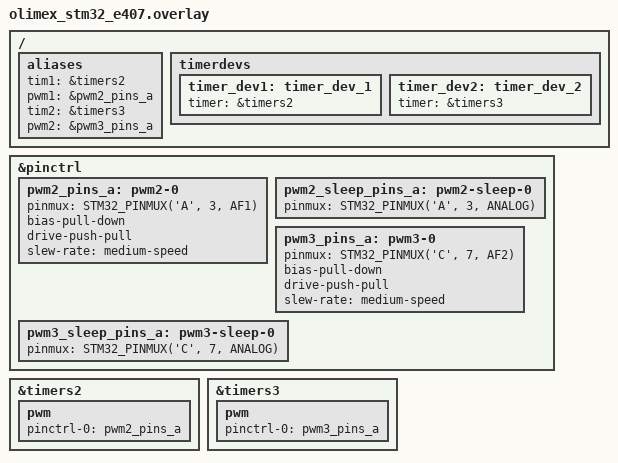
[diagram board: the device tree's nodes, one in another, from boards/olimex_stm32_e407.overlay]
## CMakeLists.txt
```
# SPDX-License-Identifier: Apache-2.0

cmake_minimum_required(VERSION 3.13.1)

set(COMPATIBLE_BOARDS olimex_stm32_e407)
if(NOT ${BOARD} IN_LIST COMPATIBLE_BOARDS)
    message(FATAL_ERROR "App $ENV{UROS_APP} not compatible with board ${BOARD}")
endif()

set(BOARD_ROOT ${CMAKE_CURRENT_LIST_DIR})

include($ENV{ZEPHYR_BASE}/cmake/app/boilerplate.cmake NO_POLICY_SCOPE)
project(microrosapp C CXX)

FILE(GLOB app_sources src/*.c)

target_sources(app PRIVATE ${app_sources})

zephyr_get_include_directories_for_lang_as_string(       C includes)
zephyr_get_system_include_directories_for_lang_as_string(C system_includes)
zephyr_get_compile_definitions_for_lang_as_string(       C definitions)
zephyr_get_compile_options_for_lang_as_string(           C options)

zephyr_get_include_directories_for_lang_as_string(       CXX includes_cxx)
zephyr_get_system_include_directories_for_lang_as_string(CXX system_includes_cxx)
zephyr_get_compile_definitions_for_lang_as_string(       CXX definitions_cxx)
zephyr_get_compile_options_for_lang_as_string(           CXX options_cxx)

set(external_project_cflags
    "${includes} ${definitions} ${options} ${system_includes}"
    )

set(external_project_cxxflags
    "${includes_cxx} ${definitions_cxx} ${options_cxx} ${system_includes_cxx}" 
    )

include(ExternalProject)

set(microros_src_dir   ${MICRO_ROS_FIRMWARE_DIR}/zephyr_apps/microros_extensions)
set(microros_build_dir ${MICRO_ROS_FIRMWARE_DIR}/build/microros_extensions)

if(CMAKE_GENERATOR STREQUAL "Unix Makefiles")
set(submake "$(MAKE)")
else()
set(submake "make")
endif()

ExternalProject_Add(
    microroslib_project                 # Name for custom target
    PREFIX     ${microros_build_dir}    # Root dir for entire project
    SOURCE_DIR ${microros_src_dir}
    BINARY_DIR ${microros_src_dir}      # This particular build system is invoked from the root
    CONFIGURE_COMMAND ""                # Skip configuring the project, e.g. with autoconf
    BUILD_COMMAND
        ${submake}
            PREFIX=${microros_src_dir}
            CC=${CMAKE_C_COMPILER}
            AR=${CMAKE_AR}
            CFLAGS=${external_project_cflags}
            CXX=${CMAKE_CXX_COMPILER}
            CXXFLAGS=${external_project_cxxflags}
            APP_META=$ENV{UROS_APP_FOLDER}/app-colcon.meta

    INSTALL_COMMAND ""      # This particular build system has no install command
    BUILD_BYPRODUCTS ${MICROROS_LIB_DIR}/libmicroros.a
    )

file(MAKE_DIRECTORY ${MICRO_ROS_FIRMWARE_DIR}/mcu_ws/install)
file(MAKE_DIRECTORY ${MICRO_ROS_FIRMWARE_DIR}/mcu_ws/install/include)

set(MICROROS_LIB_DIR     ${MICRO_ROS_FIRMWARE_DIR}/mcu_ws/install)
set(MICROROS_INCLUDE_DIR ${MICRO_ROS_FIRMWARE_DIR}/mcu_ws/install/include)

add_library(microroslib STATIC IMPORTED GLOBAL)
add_dependencies(
    microroslib
    microroslib_project
    )

add_dependencies(microroslib_project offsets_h)

set_target_properties(microroslib PROPERTIES IMPORTED_LOCATION             ${MICROROS_LIB_DIR}/libmicroros.a)
set_target_properties(microroslib PROPERTIES INTERFACE_INCLUDE_DIRECTORIES ${MICROROS_INCLUDE_DIR})

target_link_libraries(app PUBLIC microroslib)
```

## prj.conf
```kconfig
CONFIG_MAIN_STACK_SIZE=25000
CONFIG_MAIN_THREAD_PRIORITY=3

CONFIG_NEWLIB_LIBC=y
CONFIG_NEWLIB_LIBC_NANO=n
CONFIG_CPLUSPLUS=y
CONFIG_LIB_CPLUSPLUS=y
CONFIG_PTHREAD_IPC=n

CONFIG_POSIX_API=y
CONFIG_NATIVE_POSIX_TIMER=y
CONFIG_APP_LINK_WITH_POSIX_SUBSYS=y
CONFIG_POSIX_CLOCK=y

CONFIG_I2C=y
CONFIG_GPIO=y
CONFIG_PWM=y
CONFIG_SENSOR=y

CONFIG_LED_STRIP=y
CONFIG_LED_STRIP_LOG_LEVEL_DBG=y
CONFIG_WS2812_STRIP=y
CONFIG_SPI=y
CONFIG_WS2812_STRIP_GPIO=n

CONFIG_STDOUT_CONSOLE=y
CONFIG_PRINTK=y
CONFIG_USB=y
CONFIG_USB_DEVICE_STACK=y
CONFIG_USB_DEVICE_PRODUCT="Zephyr micro-ROS"
CONFIG_LOG=y
CONFIG_USB_CDC_ACM=y
CONFIG_SERIAL=y
CONFIG_UART_INTERRUPT_DRIVEN=y
CONFIG_UART_LINE_CTRL=y
CONFIG_USB_DRIVER_LOG_LEVEL_ERR=y
CONFIG_USB_DEVICE_LOG_LEVEL_ERR=y
CONFIG_USB_CDC_ACM_RINGBUF_SIZE=2048
```

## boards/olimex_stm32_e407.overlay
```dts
/{
	aliases {
		tim1 = &timers2;
		pwm1 = &pwm2_pins_a;
		tim2 = &timers3;
		pwm2 = &pwm3_pins_a;
	};

	timerdevs {
		timer_dev1: timer_dev_1 {
			timer = &timers2;
		};

		timer_dev2: timer_dev_2 {
			timer = &timers3;
		};
	};
};

&pinctrl {
	pwm2_pins_a: pwm2-0 {
		pinmux = <STM32_PINMUX('A', 3, AF1)>; /* TIM2_CH4 */
		bias-pull-down;
		drive-push-pull;
		slew-rate = "medium-speed";
	};

	pwm2_sleep_pins_a: pwm2-sleep-0 {
		pinmux = <STM32_PINMUX('A', 3, ANALOG)>; /* TIM2_CH4 */
	};

	pwm3_pins_a: pwm3-0 {
		pinmux = <STM32_PINMUX('C', 7, AF2)>; /* TIM3_CH2 */
		bias-pull-down;
		drive-push-pull;
		slew-rate = "medium-speed";
	};

	pwm3_sleep_pins_a: pwm3-sleep-0 {
		pinmux = <STM32_PINMUX('C', 7, ANALOG)>; /* TIM3_CH2 */
	};
};

&timers2 {
	status = "okay";

	pwm {
		status = "okay";
		pinctrl-0 = <&pwm2_pins_a>;
	};
};

&timers3 {
	status = "okay";

	pwm {
		status = "okay";
		pinctrl-0 = <&pwm3_pins_a>;
	};
};
```

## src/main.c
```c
#include <zephyr.h>
#include <device.h>
#include <devicetree.h>
#include <drivers/sensor.h>
#include <drivers/gpio.h>
#include <drivers/led_strip.h>
#include <drivers/pwm.h>
#include <stdio.h>
#include <sys/util.h>
#include <string.h>
#include <sys/printk.h>

#include <rcl/rcl.h>
#include <rcl/error_handling.h>
#include <rclc/rclc.h>
#include <rclc/executor.h>

#include <std_msgs/msg/bool.h>
#include <std_msgs/msg/int32.h>

#define RCCHECK(fn) { rcl_ret_t temp_rc = fn; if((temp_rc != RCL_RET_OK)){printk("Failed status on line %d: %d. Aborting.\n",__LINE__,(int)temp_rc);}}
#define RCSOFTCHECK(fn) { rcl_ret_t temp_rc = fn; if((temp_rc != RCL_RET_OK)){printk("Failed status on line %d: %d. Continuing.\n",__LINE__,(int)temp_rc);}}

//#define PWM_DRIVER	DT_ALIAS_PWM_LED0_PWMS_CONTROLLER
#define PIN	DT_GPIO_PIN(DT_ALIAS(led0), gpios)
static struct device *led;

static const struct device *pwm1;
static const struct device *pwm2;

rcl_subscription_t pwm1_subscription;
rcl_subscription_t pwm2_subscription;

std_msgs__msg__Int32 pwm1_msg;
std_msgs__msg__Int32 pwm2_msg;

void pwm1_subscription_callback(const void * msg)
{
}

void pwm2_subscription_callback(const void * msg)
{
}

void main(void)
{
	led = device_get_binding(DT_GPIO_LABEL(DT_ALIAS(led0), gpios));
	gpio_pin_configure(led, PIN, GPIO_OUTPUT_ACTIVE);

	rcl_allocator_t allocator = rcl_get_default_allocator();
	rclc_support_t support;

	// create init_options
	RCCHECK(rclc_support_init(&support, 0, NULL, &allocator));

	// create node
	rcl_node_t node;
	RCCHECK(rclc_node_init_default(&node, "bfr_hardware_node", "", &support));

	uint32_t pwm1_pinmux = DT_PROP(DT_ALIAS(pwm1), pinmux);
	uint32_t pwm2_pinmux = DT_PROP(DT_ALIAS(pwm2), pinmux);

	// ---- Devices configuration ----
	pwm1 = device_get_binding(DT_LABEL(DT_CHILD(DT_ALIAS(tim1), pwm)));
	pwm2 = device_get_binding(DT_LABEL(DT_CHILD(DT_ALIAS(tim2), pwm)));

	uint64_t cycles = 0;

	RCCHECK(rclc_subscription_init_default(&pwm1_subscription, &node, ROSIDL_GET_MSG_TYPE_SUPPORT(std_msgs, msg, Int32), "/hal/hardware/pwm1"));
	RCCHECK(rclc_subscription_init_default(&pwm2_subscription, &node, ROSIDL_GET_MSG_TYPE_SUPPORT(std_msgs, msg, Int32), "/hal/hardware/pwm2"));

	// Creating a executor
	rclc_executor_t executor;
	RCCHECK(rclc_executor_init(&executor, &support.context, 2, &allocator));
	RCCHECK(rclc_executor_add_subscription(&executor, &pwm1_subscription, &pwm1_msg, &pwm1_subscription_callback, ON_NEW_DATA));
	RCCHECK(rclc_executor_add_subscription(&executor, &pwm2_subscription, &pwm2_msg, &pwm2_subscription_callback, ON_NEW_DATA));


	pwm_get_cycles_per_sec(pwm1, pwm1_pinmux, &cycles);
	//gpio_pin_set(led, PIN, 1);

	if (pwm_pin_set_usec(pwm1, pwm1_pinmux, 1000, 1000 / 2U, 0)) {
		printk("pwm pin set fails\n");
		return;
	}	

	while (1) {
		rclc_executor_spin_some(&executor, RCL_MS_TO_NS(10));
		printk("Running once");
	}

	RCCHECK(rcl_node_fini(&node));
}
```
